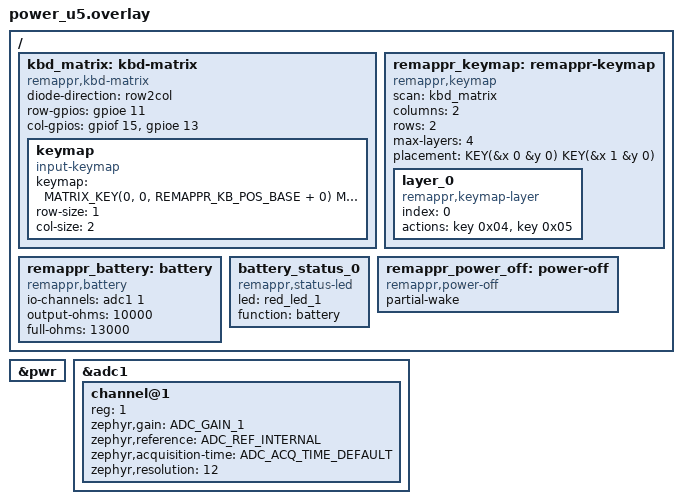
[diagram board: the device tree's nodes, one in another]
/*
 * Power U5 — Remappr shield (generated by remappr).
 *
 * Drop this directory into a remappr-firmware checkout under
 * boards/shields/power_u5/ and build with -Dremappr_SHIELD=power_u5. Verify the
 * row/col GPIO specs against your wiring — remappr derives the matrix
 * cells from physical key position, not the electrical matrix.
 *
 * SPDX-License-Identifier: Apache-2.0
 */

#include <zephyr/dt-bindings/input/input-event-codes.h>
#include <zephyr/dt-bindings/input/keymap.h>
#include <dt-bindings/remappr/keys.h>
#include <dt-bindings/remappr/layout.h>
#include <remappr/keymap-tokens.dtsi>
#include <remappr/behavior-tokens.dtsi>
#include <zephyr/dt-bindings/adc/adc.h>

/ {
	kbd_matrix: kbd-matrix {
		compatible = "remappr,kbd-matrix";
		diode-direction = "row2col";
		row-gpios =
			<&gpioe 11 GPIO_ACTIVE_HIGH>;
		col-gpios =
			<&gpiof 15 (GPIO_ACTIVE_HIGH | GPIO_PULL_DOWN)>,
			<&gpioe 13 (GPIO_ACTIVE_HIGH | GPIO_PULL_DOWN)>;

		keymap {
			compatible = "input-keymap";
			keymap = <
				MATRIX_KEY(0, 0, REMAPPR_KB_POS_BASE + 0) MATRIX_KEY(0, 1, REMAPPR_KB_POS_BASE + 1)
			>;
			row-size = <1>;
			col-size = <2>;
		};
	};

	remappr_keymap: remappr-keymap {
		compatible = "remappr,keymap";
		scan = <&kbd_matrix>;
		columns = <2>;
		rows = <2>;
		max-layers = <4>;
		placement = <
				KEY(&x 0 &y 0) KEY(&x 1 &y 0)
		>;
		layer_0 {
			compatible = "remappr,keymap-layer";
			index = <0>;
			actions = <
				&key 0x04 &key 0x05
			>;
		};
	};
};

/ {
	remappr_battery: battery {
		compatible = "remappr,battery";
		io-channels = <&adc1 1>;
		output-ohms = <10000>;
		full-ohms = <13000>;
	};
};

/ {
	battery_status_0 {
		compatible = "remappr,status-led";
		led = <&red_led_1>;
		function = "battery";
	};
};

/ {
	remappr_power_off: power-off {
		compatible = "remappr,power-off";
		partial-wake;
	};
};

/* STM32 shutdown wakes on the PWR wake-up lines only. */
&pwr {
	status = "okay";
};

&adc1 {
	status = "okay";
	#address-cells = <1>;
	#size-cells = <0>;

	channel@1 {
		reg = <1>;
		zephyr,gain = "ADC_GAIN_1";
		zephyr,reference = "ADC_REF_INTERNAL";
		zephyr,acquisition-time = <ADC_ACQ_TIME_DEFAULT>;
		zephyr,resolution = <12>;
	};
};
